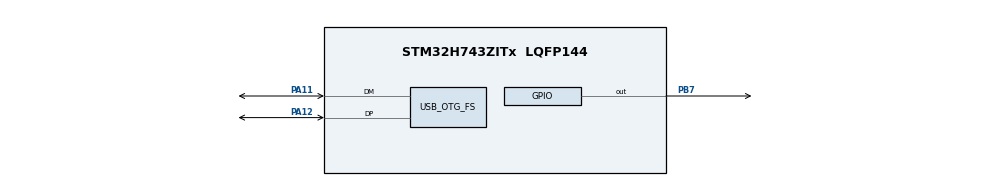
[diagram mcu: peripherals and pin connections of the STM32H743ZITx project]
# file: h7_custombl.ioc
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Mcu.Family=STM32H7
Mcu.Name=STM32H743ZITx
Mcu.Package=LQFP144
NVIC.OTG_FS_IRQn=true\:0\:0\:false\:false\:true\:false\:true
NVIC.PriorityGroup=NVIC_PRIORITYGROUP_4
PA11.Mode=Device_Only
PA11.Signal=USB_OTG_FS_DM
PA12.Mode=Device_Only
PA12.Signal=USB_OTG_FS_DP
PB7.Signal=GPIO_Output
ProjectManager.HeapSize=0x200
ProjectManager.StackSize=0x400
ProjectManager.TargetToolchain=STM32CubeIDE
RCC.48MHZClocksFreq_Value=24000000
RCC.ADCFreq_Value=8062500
RCC.AHBFreq_Value=216000000
RCC.APB1CLKDivider=RCC_HCLK_DIV4
RCC.APB1Freq_Value=76000000
RCC.APB1TimFreq_Value=108000000
RCC.APB2CLKDivider=RCC_HCLK_DIV2
RCC.APB2Freq_Value=76000000
RCC.APB2TimFreq_Value=216000000
RCC.APB3Freq_Value=76000000
RCC.APB4Freq_Value=76000000
RCC.CortexFreq_Value=76000000
RCC.DIVM1=1
RCC.DIVN1=38
RCC.DIVQ1=4
RCC.HCLKFreq_Value=76000000
RCC.HSE_VALUE=8000000
RCC.HSI_VALUE=64000000
RCC.PLLM=25
RCC.PLLMUL=RCC_PLL_MUL9
RCC.PLLN=432
RCC.PLLQ=9
RCC.PLLSourceVirtual=RCC_PLLSOURCE_CSI
RCC.PRESCALERUSB=RCC_USBCLKSOURCE_PLL_DIV1_5
RCC.PWR_Regulator_Voltage_Scale=PWR_REGULATOR_VOLTAGE_SCALE1
RCC.SYSCLKFreq_VALUE=76000000
RCC.SYSCLKSource=RCC_SYSCLKSOURCE_PLLCLK
RCC.SYSCLKSourceVirtual=RCC_SYSCLKSOURCE_PLLCLK
RCC.USBCLockSelection=RCC_USBCLKSOURCE_HSI48
RCC.USBFreq_Value=48000000
RCC.VCOOutputFreq_Value=432000000
USB_DEVICE.CLASS_NAME_FS=CDC
USB_DEVICE.VirtualMode-CDC_FS=Cdc
USB_DEVICE.VirtualModeFS=Cdc_FS
USB_OTG_FS.VirtualMode=Device_Only
VP_USB_DEVICE_VS_USB_DEVICE_CDC_FS.Mode=CDC_FS
board=NUCLEO-H743ZI

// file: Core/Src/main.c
/* USER CODE BEGIN Header */
/**
  ******************************************************************************
  * @file           : main.c
  * @brief          : Main program body
  ******************************************************************************
  * @attention
  *
  * <h2><center>&copy; Copyright (c) 2020 STMicroelectronics.
  * All rights reserved.</center></h2>
  *
  * This software component is licensed by ST under BSD 3-Clause license,
  * the "License"; You may not use this file except in compliance with the
  * License. You may obtain a copy of the License at:
  *                        opensource.org/licenses/BSD-3-Clause
  *
  ******************************************************************************
  */
/* USER CODE END Header */

#include "main.h"
#include "usb_device.h"

/* USER CODE BEGIN Includes */
#include "usbd_cdc_if.h"
/* USER CODE END Includes */

/* USER CODE BEGIN PV */
//uint8_t rec_buffer[7];
uint8_t flag = 0;
extern uint8_t* Buf;
/* USER CODE END PV */

void SystemClock_Config(void);
static void MX_GPIO_Init(void);
/* USER CODE BEGIN PFP */
void JumpToBootloader(void)
{
  uint32_t i=0;
  void (*SysMemBootJump)(void);
  /* Set the address of the entry point to bootloader */
     volatile uint32_t BootAddr = 0x1FF09800;
  /* Disable all interrupts */
     __disable_irq();
  /* Disable Systick timer */
     SysTick->CTRL = 0;
  /* Set the clock to the default state */
     HAL_RCC_DeInit();
  /* Clear Interrupt Enable Register & Interrupt Pending Register */
     for (i=0;i<5;i++)
     {
	  NVIC->ICER[i]=0xFFFFFFFF;
	  NVIC->ICPR[i]=0xFFFFFFFF;
     }
  /* Re-enable all interrupts */
     __enable_irq();
  /* Set up the1ff09800 jump to booloader address + 4 */
     SysMemBootJump = (void (*)(void)) (*((uint32_t *) ((BootAddr + 4))));
  /* Set the main stack pointer to the bootloader stack */
     __set_MSP(*(uint32_t *)BootAddr);
  /* Call the function to jump to bootloader location */
     SysMemBootJump();
  /* Jump is done successfully */
     while (1)
     {
      /* Code should never reach this loop */
     }
}
/* USER CODE END PFP */

int main(void)
{

  /* MCU Configuration--------------------------------------------------------*/

  /* Reset of all peripherals, Initializes the Flash interface and the Systick. */
  HAL_Init();

  /* Configure the system clock */
  SystemClock_Config();

  /* Initialize all configured peripherals */
  MX_GPIO_Init();
  MX_USB_DEVICE_Init();

  /* Infinite loop */
  /* USER CODE BEGIN WHILE */
  while (1)
  {
	  char mystr[] = "hello\n\r";
	  CDC_Transmit_FS((uint8_t*)mystr,sizeof(mystr));

//	  if(flag == 1)
//	  {
//		  HAL_GPIO_TogglePin(GPIOB, GPIO_PIN_7);
//		  HAL_Delay(1000);
//		  JumpToBootloader();
//		  flag = 0;
//	  }
//	  HAL_Delay(1000);
    /* USER CODE END WHILE */

  }
}

void SystemClock_Config(void)
{
  RCC_OscInitTypeDef RCC_OscInitStruct = {0};
  RCC_ClkInitTypeDef RCC_ClkInitStruct = {0};
  RCC_PeriphCLKInitTypeDef PeriphClkInitStruct = {0};

  /** Supply configuration update enable
  */
  HAL_PWREx_ConfigSupply(PWR_LDO_SUPPLY);
  /** Configure the main internal regulator output voltage
  */
  __HAL_PWR_VOLTAGESCALING_CONFIG(PWR_REGULATOR_VOLTAGE_SCALE1);

  while(!__HAL_PWR_GET_FLAG(PWR_FLAG_VOSRDY)) {}
  /** Initializes the CPU, AHB and APB busses clocks
  */
  RCC_OscInitStruct.OscillatorType = RCC_OSCILLATORTYPE_HSI48|RCC_OSCILLATORTYPE_CSI;
  RCC_OscInitStruct.HSI48State = RCC_HSI48_ON;
  RCC_OscInitStruct.CSIState = RCC_CSI_ON;
  RCC_OscInitStruct.CSICalibrationValue = 16;
  RCC_OscInitStruct.PLL.PLLState = RCC_PLL_ON;
  RCC_OscInitStruct.PLL.PLLSource = RCC_PLLSOURCE_CSI;
  RCC_OscInitStruct.PLL.PLLM = 1;
  RCC_OscInitStruct.PLL.PLLN = 38;
  RCC_OscInitStruct.PLL.PLLP = 2;
  RCC_OscInitStruct.PLL.PLLQ = 4;
  RCC_OscInitStruct.PLL.PLLR = 2;
  RCC_OscInitStruct.PLL.PLLRGE = RCC_PLL1VCIRANGE_2;
  RCC_OscInitStruct.PLL.PLLVCOSEL = RCC_PLL1VCOMEDIUM;
  RCC_OscInitStruct.PLL.PLLFRACN = 0;
  if (HAL_RCC_OscConfig(&RCC_OscInitStruct) != HAL_OK)
  {
    Error_Handler();
  }
  /** Initializes the CPU, AHB and APB busses clocks
  */
  RCC_ClkInitStruct.ClockType = RCC_CLOCKTYPE_HCLK|RCC_CLOCKTYPE_SYSCLK
                              |RCC_CLOCKTYPE_PCLK1|RCC_CLOCKTYPE_PCLK2
                              |RCC_CLOCKTYPE_D3PCLK1|RCC_CLOCKTYPE_D1PCLK1;
  RCC_ClkInitStruct.SYSCLKSource = RCC_SYSCLKSOURCE_PLLCLK;
  RCC_ClkInitStruct.SYSCLKDivider = RCC_SYSCLK_DIV1;
  RCC_ClkInitStruct.AHBCLKDivider = RCC_HCLK_DIV1;
  RCC_ClkInitStruct.APB3CLKDivider = RCC_APB3_DIV1;
  RCC_ClkInitStruct.APB1CLKDivider = RCC_APB1_DIV1;
  RCC_ClkInitStruct.APB2CLKDivider = RCC_APB2_DIV1;
  RCC_ClkInitStruct.APB4CLKDivider = RCC_APB4_DIV1;

  if (HAL_RCC_ClockConfig(&RCC_ClkInitStruct, FLASH_LATENCY_1) != HAL_OK)
  {
    Error_Handler();
  }
  PeriphClkInitStruct.PeriphClockSelection = RCC_PERIPHCLK_USB;
  PeriphClkInitStruct.UsbClockSelection = RCC_USBCLKSOURCE_HSI48;
  if (HAL_RCCEx_PeriphCLKConfig(&PeriphClkInitStruct) != HAL_OK)
  {
    Error_Handler();
  }
  /** Enable USB Voltage detector
  */
  HAL_PWREx_EnableUSBVoltageDetector();
}

static void MX_GPIO_Init(void)
{
  GPIO_InitTypeDef GPIO_InitStruct = {0};

  /* GPIO Ports Clock Enable */
  __HAL_RCC_GPIOA_CLK_ENABLE();
  __HAL_RCC_GPIOB_CLK_ENABLE();

  /*Configure GPIO pin Output Level */
  HAL_GPIO_WritePin(GPIOB, GPIO_PIN_7, GPIO_PIN_RESET);

  /*Configure GPIO pin : PB7 */
  GPIO_InitStruct.Pin = GPIO_PIN_7;
  GPIO_InitStruct.Mode = GPIO_MODE_OUTPUT_PP;
  GPIO_InitStruct.Pull = GPIO_NOPULL;
  GPIO_InitStruct.Speed = GPIO_SPEED_FREQ_LOW;
  HAL_GPIO_Init(GPIOB, &GPIO_InitStruct);

}

void Error_Handler(void)
{
}

/************************ (C) COPYRIGHT STMicroelectronics *****END OF FILE****/
